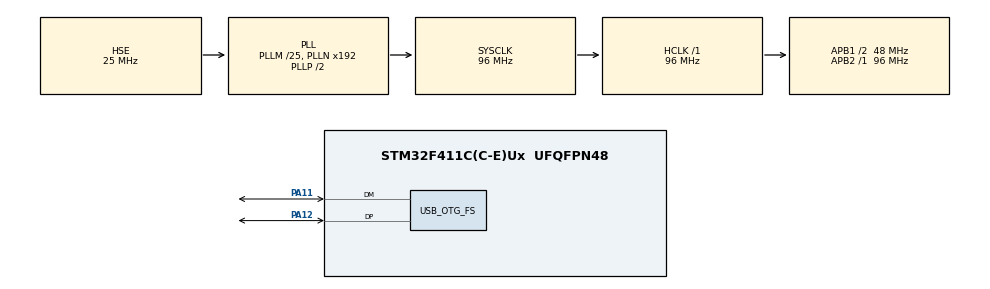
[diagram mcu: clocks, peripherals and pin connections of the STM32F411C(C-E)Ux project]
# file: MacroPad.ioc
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Mcu.Family=STM32F4
Mcu.Name=STM32F411C(C-E)Ux
Mcu.Package=UFQFPN48
NVIC.OTG_FS_IRQn=true\:0\:0\:false\:false\:true\:false\:true\:true
NVIC.PriorityGroup=NVIC_PRIORITYGROUP_4
PA11.Mode=Device_Only
PA11.Signal=USB_OTG_FS_DM
PA12.Mode=Device_Only
PA12.Signal=USB_OTG_FS_DP
PA13.Mode=Serial_Wire
PA13.Signal=SYS_JTMS-SWDIO
PA14.Mode=Serial_Wire
PA14.Signal=SYS_JTCK-SWCLK
PH0\ -\ OSC_IN.Mode=HSE-External-Oscillator
PH0\ -\ OSC_IN.Signal=RCC_OSC_IN
PH1\ -\ OSC_OUT.Mode=HSE-External-Oscillator
PH1\ -\ OSC_OUT.Signal=RCC_OSC_OUT
ProjectManager.HeapSize=0x400
ProjectManager.StackSize=0x800
ProjectManager.TargetToolchain=STM32CubeIDE
RCC.48MHZClocksFreq_Value=48000000
RCC.AHBFreq_Value=96000000
RCC.APB1CLKDivider=RCC_HCLK_DIV2
RCC.APB1Freq_Value=48000000
RCC.APB1TimFreq_Value=96000000
RCC.APB2Freq_Value=96000000
RCC.APB2TimFreq_Value=96000000
RCC.CortexFreq_Value=96000000
RCC.HCLKFreq_Value=96000000
RCC.HSE_VALUE=25000000
RCC.HSI_VALUE=16000000
RCC.LSE_VALUE=32768
RCC.PLLM=25
RCC.SYSCLKFreq_VALUE=96000000
RCC.SYSCLKSource=RCC_SYSCLKSOURCE_PLLCLK
RCC.VCOOutputFreq_Value=192000000
USB_DEVICE.CLASS_NAME_FS=HID
USB_DEVICE.VirtualMode=Hid
USB_DEVICE.VirtualModeFS=Hid_FS
USB_OTG_FS.VirtualMode=Device_Only
VP_USB_DEVICE_VS_USB_DEVICE_HID_FS.Mode=HID_FS
board=custom

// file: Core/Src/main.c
/* USER CODE BEGIN Header */
/**
  ******************************************************************************
  * @file           : main.c
  * @brief          : Main program body
  ******************************************************************************
  * @attention
  *
  * Copyright (c) 2026 STMicroelectronics.
  * All rights reserved.
  *
  * This software is licensed under terms that can be found in the LICENSE file
  * in the root directory of this software component.
  * If no LICENSE file comes with this software, it is provided AS-IS.
  *
  ******************************************************************************
  */
/* USER CODE END Header */
#include "main.h"
#include "usb_device.h"
#include "ui.h"

/* USER CODE BEGIN Includes */
#include "usbd_hid.h"
extern USBD_HandleTypeDef hUsbDeviceFS;

/* USER CODE END Includes */

/* USER CODE BEGIN PTD */
typedef struct {
  uint8_t cpu;
  uint8_t ram;
  uint8_t battery;
  uint8_t temp;
  uint8_t seq;
  uint8_t valid;
} PcStats_t;

/* USER CODE END PTD */

/* USER CODE BEGIN PD */
#define HID_STATE_IDLE 0U
/* USER CODE END PD */

/* USER CODE BEGIN PV */
PcStats_t pc_stats = { 0xFF, 0xFF, 0xFF, 0xFF, 0, 0 };
uint32_t  last_rx_tick = 0;
/* USER CODE END PV */

void SystemClock_Config(void);
static void MX_GPIO_Init(void);

/* USER CODE BEGIN 0 */
static void handle_rx_packet(void)
{
  if (hid_rx_buf[0] == 0x03U && hid_rx_buf[1] == 0x01U)
  {
    pc_stats.cpu     = hid_rx_buf[2];
    pc_stats.ram     = hid_rx_buf[3];
    pc_stats.battery = hid_rx_buf[4];
    pc_stats.temp    = hid_rx_buf[5];
    pc_stats.seq     = hid_rx_buf[6];
    pc_stats.valid   = 1U;
    last_rx_tick = HAL_GetTick();
  }
}
static uint8_t hid_ready(void)
{
  USBD_HID_HandleTypeDef *h = (USBD_HID_HandleTypeDef *)hUsbDeviceFS.pClassData;
  return (hUsbDeviceFS.dev_state == USBD_STATE_CONFIGURED) &&
         (h != NULL) && (h->state == HID_STATE_IDLE);
}

static uint8_t wait_hid_ready(uint32_t timeout_ms)
{
  uint32_t t0 = HAL_GetTick();
  while (!hid_ready()) {
    if ((HAL_GetTick() - t0) > timeout_ms) { return 0U; }
  }
  return 1U;
}

static void kbd_send(uint8_t mod, uint8_t key)
{
  uint8_t press[9]   = { 0x01, mod, 0x00, key, 0, 0, 0, 0, 0 };
  uint8_t release[9] = { 0x01, 0, 0, 0, 0, 0, 0, 0, 0 };

  if (!wait_hid_ready(50U))  { return; }
  USBD_HID_SendReport(&hUsbDeviceFS, press, 9);
  if (!wait_hid_ready(200U)) { return; }
  USBD_HID_SendReport(&hUsbDeviceFS, release, 9);
}
/* USER CODE END 0 */

int main(void)
{

  /* MCU Configuration--------------------------------------------------------*/

  /* Reset of all peripherals, Initializes the Flash interface and the Systick. */
  HAL_Init();

  /* Configure the system clock */
  SystemClock_Config();

  /* Initialize all configured peripherals */
  MX_GPIO_Init();
  MX_USB_DEVICE_Init();
  /* USER CODE BEGIN 2 */
  ui_init(kbd_send);
  /* USER CODE END 2 */

  /* Infinite loop */
  while (1)
  {

    /* USER CODE BEGIN 3 */
	    if (hid_rx_ready)
	    {
	      hid_rx_ready = 0U;
	      handle_rx_packet();
	    }
	    uint8_t link = pc_stats.valid && ((HAL_GetTick() - last_rx_tick) < 3000U);
	    ui_update_stats(pc_stats.cpu, pc_stats.ram, pc_stats.battery,
	                    pc_stats.temp, pc_stats.seq, link);
	    ui_poll();
  }
  /* USER CODE END 3 */
}

void SystemClock_Config(void)
{
  RCC_OscInitTypeDef RCC_OscInitStruct = {0};
  RCC_ClkInitTypeDef RCC_ClkInitStruct = {0};

  /** Configure the main internal regulator output voltage
  */
  __HAL_RCC_PWR_CLK_ENABLE();
  __HAL_PWR_VOLTAGESCALING_CONFIG(PWR_REGULATOR_VOLTAGE_SCALE1);

  /** Initializes the RCC Oscillators according to the specified parameters
  * in the RCC_OscInitTypeDef structure.
  */
  RCC_OscInitStruct.OscillatorType = RCC_OSCILLATORTYPE_HSE;
  RCC_OscInitStruct.HSEState = RCC_HSE_ON;
  RCC_OscInitStruct.PLL.PLLState = RCC_PLL_ON;
  RCC_OscInitStruct.PLL.PLLSource = RCC_PLLSOURCE_HSE;
  RCC_OscInitStruct.PLL.PLLM = 25;
  RCC_OscInitStruct.PLL.PLLN = 192;
  RCC_OscInitStruct.PLL.PLLP = RCC_PLLP_DIV2;
  RCC_OscInitStruct.PLL.PLLQ = 4;
  if (HAL_RCC_OscConfig(&RCC_OscInitStruct) != HAL_OK)
  {
    Error_Handler();
  }

  /** Initializes the CPU, AHB and APB buses clocks
  */
  RCC_ClkInitStruct.ClockType = RCC_CLOCKTYPE_HCLK|RCC_CLOCKTYPE_SYSCLK
                              |RCC_CLOCKTYPE_PCLK1|RCC_CLOCKTYPE_PCLK2;
  RCC_ClkInitStruct.SYSCLKSource = RCC_SYSCLKSOURCE_PLLCLK;
  RCC_ClkInitStruct.AHBCLKDivider = RCC_SYSCLK_DIV1;
  RCC_ClkInitStruct.APB1CLKDivider = RCC_HCLK_DIV2;
  RCC_ClkInitStruct.APB2CLKDivider = RCC_HCLK_DIV1;

  if (HAL_RCC_ClockConfig(&RCC_ClkInitStruct, FLASH_LATENCY_3) != HAL_OK)
  {
    Error_Handler();
  }
}

static void MX_GPIO_Init(void)
{

  /* GPIO Ports Clock Enable */
  __HAL_RCC_GPIOH_CLK_ENABLE();
  __HAL_RCC_GPIOA_CLK_ENABLE();

}

void Error_Handler(void)
{
  __disable_irq();
  while (1)
  {
  }
}

/* Force GitHub language re-index */
